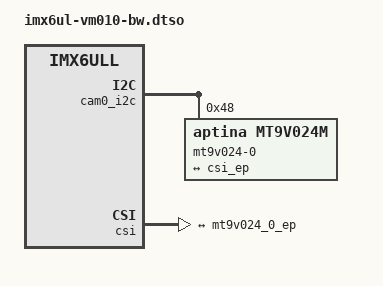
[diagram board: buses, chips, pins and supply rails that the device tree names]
// SPDX-License-Identifier: (GPL-2.0+ OR MIT)
/*
 * Copyright (C) 2021 PHYTEC Messtechnik GmbH
 * Author: Stefan Riedmueller <s.riedmueller@phytec.de>
 */

/dts-v1/;
/plugin/;

#include <dt-bindings/clock/imx6ul-clock.h>

/ {
	compatible = "phytec,imx6ul-pbacd10", "phytec,imx6ull-pbacd10";
};

&cam0_i2c {
	#address-cells = <1>;
	#size-cells = <0>;

	mt9v024-0@48 {
		compatible = "aptina,mt9v024m";
		reg = <0x48>;

		clocks = <&clks IMX6UL_CLK_CSI>;
		clock-names = "csi_mclk";

		port {
			mt9v024_0_ep: endpoint {
				remote-endpoint = <&csi_ep>;
				link-frequencies = /bits/ 64 <27000000>;
				bus-type = <5>; /* Parallel */
				bus-width = <8>;
				hsync-active = <1>;
				vsync-active = <1>;
			};
		};
	};
};

&csi {
	port {
		csi_ep: endpoint {
			remote-endpoint = <&mt9v024_0_ep>;
		};
	};
};
